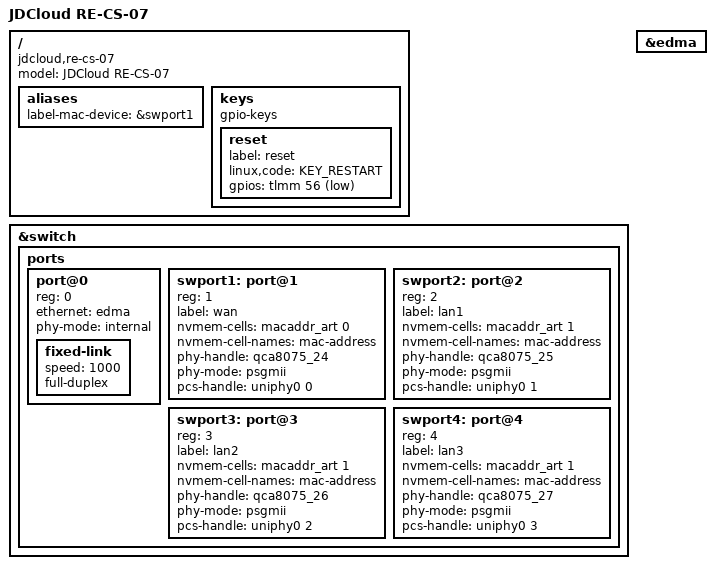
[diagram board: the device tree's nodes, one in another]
// SPDX-License-Identifier: GPL-2.0-or-later OR MIT

/dts-v1/;

#include "ipq6010-re-cs.dtsi"

/ {
	model = "JDCloud RE-CS-07";
	compatible = "jdcloud,re-cs-07", "qcom,ipq6018";

	aliases {
		label-mac-device = &swport1;
	};

	keys {
		compatible = "gpio-keys";

		reset {
			label = "reset";
			linux,code = <KEY_RESTART>;
			gpios = <&tlmm 56 GPIO_ACTIVE_LOW>;
		};
	};
};

&switch {
	status = "okay";

	ports {
		#address-cells = <1>;
		#size-cells = <0>;

		port@0 {
			reg = <0>;
			ethernet = <&edma>;
			phy-mode = "internal";

			fixed-link {
				speed = <1000>;
				full-duplex;
			};
		};

		swport1: port@1 {
			reg = <1>;
			label = "wan";
			nvmem-cells = <&macaddr_art 0>;
			nvmem-cell-names = "mac-address";
			phy-handle = <&qca8075_24>;
			phy-mode = "psgmii";
			pcs-handle = <&uniphy0 0>;
		};

		swport2: port@2 {
			reg = <2>;
			label = "lan1";
			nvmem-cells = <&macaddr_art 1>;
			nvmem-cell-names = "mac-address";
			phy-handle = <&qca8075_25>;
			phy-mode = "psgmii";
			pcs-handle = <&uniphy0 1>;
		};

		swport3: port@3 {
			reg = <3>;
			label = "lan2";
			nvmem-cells = <&macaddr_art 1>;
			nvmem-cell-names = "mac-address";
			phy-handle = <&qca8075_26>;
			phy-mode = "psgmii";
			pcs-handle = <&uniphy0 2>;
		};

		swport4: port@4 {
			reg = <4>;
			label = "lan3";
			nvmem-cells = <&macaddr_art 1>;
			nvmem-cell-names = "mac-address";
			phy-handle = <&qca8075_27>;
			phy-mode = "psgmii";
			pcs-handle = <&uniphy0 3>;
		};
	};
};

&edma {
	status = "okay";
};
